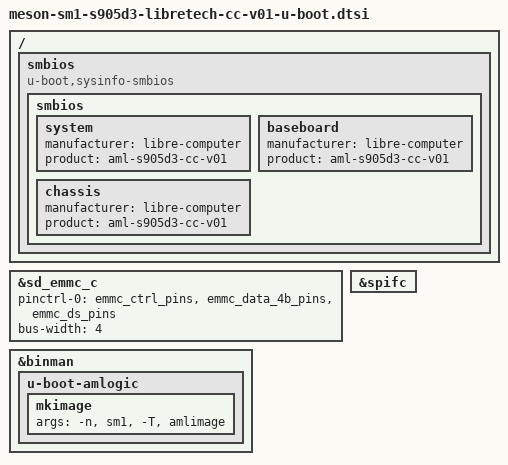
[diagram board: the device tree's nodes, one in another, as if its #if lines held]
// SPDX-License-Identifier: (GPL-2.0+ OR MIT)

#include "meson-g12-common-u-boot.dtsi"

/ {
	smbios {
		compatible = "u-boot,sysinfo-smbios";

		smbios {
			system {
				manufacturer = "libre-computer";
				product = "aml-s905d3-cc-v01";
			};

			baseboard {
				manufacturer = "libre-computer";
				product = "aml-s905d3-cc-v01";
			};

			chassis {
				manufacturer = "libre-computer";
				product = "aml-s905d3-cc-v01";
			};
		};
	};
};

&sd_emmc_c {
	pinctrl-0 = <&emmc_ctrl_pins>, <&emmc_data_4b_pins>, <&emmc_ds_pins>;
	bus-width = <4>;
};

&spifc {
	status = "okay";
};

#if defined(CONFIG_BINMAN)
&binman {
	u-boot-amlogic {
		mkimage {
			args = "-n", "sm1", "-T", "amlimage";
		};
	};
};
#endif

#ifdef CONFIG_SCMI_FIRMWARE
#include "meson-sm1-scmi-u-boot.dtsi"
#endif
